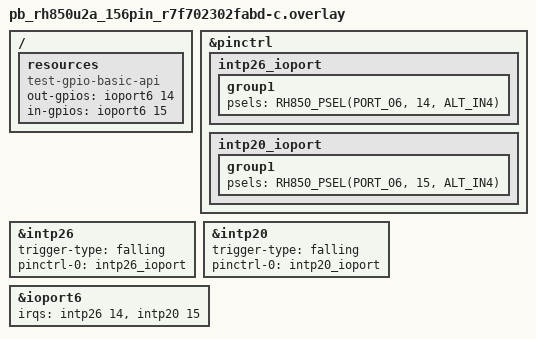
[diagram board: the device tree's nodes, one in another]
/*
 * Copyright (c) 2026 Renesas Electronics Corporation
 * SPDX-License-Identifier: Apache-2.0
 */

/ {
	resources {
		compatible = "test-gpio-basic-api";
		out-gpios = <&ioport6 14 GPIO_ACTIVE_HIGH>;
		in-gpios = <&ioport6 15 GPIO_ACTIVE_HIGH>;
	};
};

&pinctrl {
	intp26_ioport: intp26_ioport {
		group1 {
			psels = <RH850_PSEL(PORT_06, 14, ALT_IN4)>;
		};
	};

	intp20_ioport: intp20_ioport {
		group1 {
			psels = <RH850_PSEL(PORT_06, 15, ALT_IN4)>;
		};
	};
};

&intp26 {
	trigger-type = "falling";
	pinctrl-0 = <&intp26_ioport>;
	pinctrl-names = "default";
	status = "okay";
};

&intp20 {
	trigger-type = "falling";
	pinctrl-0 = <&intp20_ioport>;
	pinctrl-names = "default";
	status = "okay";
};

&ioport6 {
	irqs = <&intp26 14>, <&intp20 15>;
	status = "okay";
};
